# EFR32BG22C224F512IM40 register map
Vendor: Silicon Labs; Series: EFR32; File version: C
Registers are 32-bit, read-write, reset 0x0 unless marked. A register's access mark holds for its fields unless they carry their own. Offsets are from the block's base; [hi:lo] are bit positions; {n}, {i} and the like mark numbered series; 'fields as' and 'values as' point back to an identical list.

## MODEM_S — MODEM_S Registers
Base 0xA8014000
Same registers: MODEM_NS 0xB8014000
0x00 IPVERSION ro reset 0x1
0x04 EN
  [0] EN — Enable peripheral clock to this module
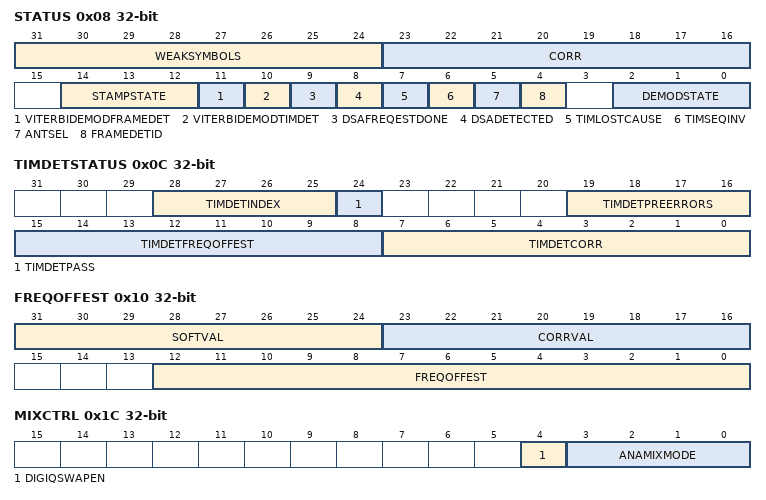
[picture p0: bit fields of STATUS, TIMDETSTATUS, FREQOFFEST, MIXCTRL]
0x08 STATUS ro
  [31:24] WEAKSYMBOLS
  [23:16] CORR — Correlation
  [14:12] STAMPSTATE — BLE Viterbi Demod Timing Stamp
  [11] VITERBIDEMODFRAMEDET — Viterbi Demod frame detected
  [10] VITERBIDEMODTIMDET — Viterbi Demod timing detected
  [9] DSAFREQESTDONE — DSA frequency estimation complete
  [8] DSADETECTED
  [7] TIMLOSTCAUSE — Timing Lost Cause
    0=LOWCORR (Timing lost during Preamble Search or due to low correlation value during Frame Search.); 1=TIMEOUT (Timing lost due to incorrect symbols detected during Frame Search.)
  [6] TIMSEQINV — Timing Sequence Inverted
  [5] ANTSEL — Selected Antenna
    0=ANTENNA0 (Antenna 0 is selected (ANT0 = 1 and ANT1 = 0).); 1=ANTENNA1 (Antenna 1 is selected (ANT0 = 0 and ANT1 = 1).)
  [4] FRAMEDETID — Frame Detected ID
    0=FRAMEDET0 (Last frame was detected with sync word defined in SYNC0.); 1=FRAMEDET1 (Last frame was detected with sync word defined in SYNC1.)
  [2:0] DEMODSTATE
    0=OFF (Off state); 1=TIMINGSEARCH; 2=PRESEARCH (Preamble search); 3=FRAMESEARCH; 4=RXFRAME (Payload Detection); 5=FRAMEDETMODE0 (Timing search with sliding window (FDM0))
0x0C TIMDETSTATUS ro
  [28:25] TIMDETINDEX — Timing detection index
  [24] TIMDETPASS — Timing detection pass
  [19:16] TIMDETPREERRORS — Preamble errors
  [15:8] TIMDETFREQOFFEST — Frequency offset estimate
  [7:0] TIMDETCORR — Correlation value
0x10 FREQOFFEST ro
  [31:24] SOFTVAL — Soft detection value
  [23:16] CORRVAL — Correlation value
  [12:0] FREQOFFEST — Frequency offset estimate
0x14 AFCADJRX ro
  [18:0] AFCADJRX — AFC adjustment for RX
0x18 AFCADJTX ro
  [18:0] AFCADJTX — AFC adjustment for TX
0x1C MIXCTRL
  [4] DIGIQSWAPEN — Digital I/Q swap enable
  [3:0] ANAMIXMODE — Analog receiver mixer mode of operation
    0=NORMAL (The analog mixer operates in its normal mode); 1=IPQPIQSWAP (I path is positive, Q path is positive, I and Q are swapped); 2=IPQN (I path is positive, Q path is negative); 3=IPQNIQSWAP (I path is positive, Q path is negative, I and Q are swapped); 4=INQP (I path is negative, Q path is positive); 5=INQPIQSWAP (I path is negative, Q path is positive, I and Q are swapped); 6=INQN (I path is negative, Q path is negative); 7=INQNIQSWAP (I path is negative, Q path is negative, I and Q are swapped); 8=UPCONVERT (Control the analog receiver mixer such that the analog mixer performs a digital up-conversion on the mixer output, with the frequency set by the DEC0 and CFOSR settings. This mode may be used to perform RF loopback using the normal synthesizer both for transmit and receive, and still get a positive IF frequency on the IF receive signal.); 9=DOWNCONVERT (Control the analog receiver mixer such that the analog mixer performs a digital down-conversion on the mixer output, with the frequency set by the DEC0 and CFOSR settings.)
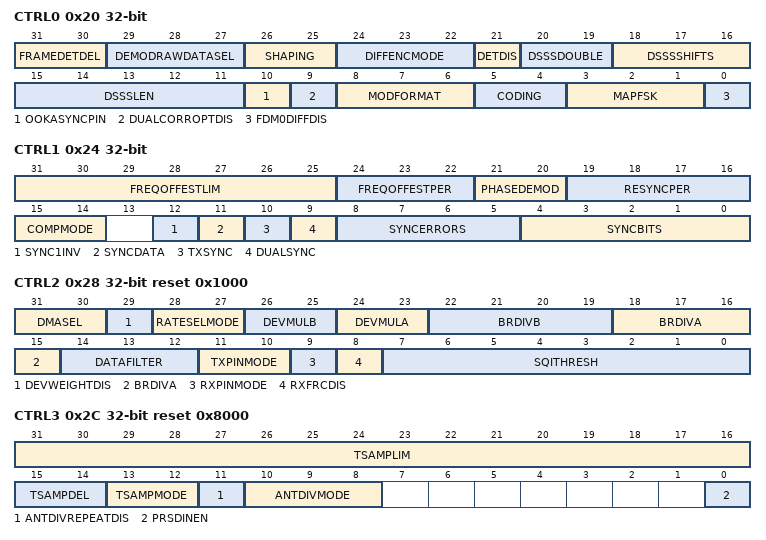
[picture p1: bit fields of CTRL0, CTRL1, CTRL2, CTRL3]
0x20 CTRL0
  [31:30] FRAMEDETDEL — FRAMEDET delay
    0=DEL0 (No delay); 1=DEL8 (8 baud delay); 2=DEL16 (16 baud delay); 3=DEL32 (32 baud delay)
  [29:27] DEMODRAWDATASEL — Demod raw data select
    0=DIS (Disabled.); 1=ENTROPY (1-bit entropy source extracted from the RF receive chain, to be used for random number generation.); 2=ADC (2 * 3-bit I and Q ADC data.); 3=FILTLSB (2 * 16-bit I and Q channel filtered data downmixed to zero-IF. The receive signal chain has 19 bits dynamic range at this point, and the FILTLSB setting outputs the 16 least significant bits (with saturation).); 4=FILTMSB (2 * 16-bit I and Q channel filtered data downmixed to zero-IF. The receive signal chain has 19 bits dynamic range at this point, and the FILTMSB setting outputs the 16 most significant bits (with truncation).); 5=FILTFULL (2 * 19-bit I and Q channel filtered data downmixed to zero-IF. The FILTFULL option will output all 19 bits of dynamic range, sign extended to 32 bits.); 6=FREQ (8-bit received frequency data (or logarithmic amplitude for ASK/OOK).); 7=DEMOD (8-bit demodulated data (freq/amp/phase). When coherent detection is enabled, only the in-phase component is selected.)
  [26:25] SHAPING — Shaping filter
    0=DISABLED (Filter disabled.); 1=ODDLENGTH (Filter has odd length. Filter uses coefficients 0,1,2,3,4,5,6,7,8,7,6,5,4,3,2,1,0.); 2=EVENLENGTH (Filter has even length. Filter uses coefficients 0,1,2,3,4,5,6,7,7,6,5,4,3,2,1,0.); 3=ASYMMETRIC (Filter has asymmetrical coefficients. Filter uses coefficients 0,1,2,3,4,5,6,7.)
  [24:22] DIFFENCMODE — Differential encoding mode
    0=DIS (Differential Encoding is disabled.); 1=RR0 (Transmit the XOR-ed value of the Raw symbol and the last Raw symbol. Initial Raw symbol is 0.); 2=RE0 (Transmit the XOR-ed value of the Raw symbol and the last Encoded symbol. Initial Encoded symbol is 0.); 3=RR1 (Transmit the XOR-ed value of the Raw symbol and the last Raw symbol. Initial Raw symbol is 1.); 4=RE1 (Transmit the XOR-ed value of the Raw symbol and the last Encoded symbol. Initial Encoded symbol is 1.)
  [21] DETDIS — Detection disable
  [20:19] DSSSDOUBLE
    0=DIS (Doubling is disabled.); 1=INV (Doubling is enabled by using inverted symbols.); 2=CONJ (Doubling is enabled by using complex conjugated symbols.)
  [18:16] DSSSSHIFTS
    0=NOSHIFT (No symbols are defined by shifting.); 1=SHIFT1 (Next symbol generated by 1 cyclic shift.); 2=SHIFT2 (Next symbol generated by 2 cyclic shifts.); 3=SHIFT4 (Next symbol generated by 4 cyclic shifts.); 4=SHIFT8 (Next symbol generated by 8 cyclic shifts.); 5=SHIFT16 (Next symbol generated by 16 cyclic shifts.)
  [15:11] DSSSLEN — DSSS length
  [10] OOKASYNCPIN — OOK asynchronous pin mode
  [9] DUALCORROPTDIS — Dual Correlation Optimization Disable
  [8:6] MODFORMAT — Modulation format
    0=FSK2 (Frequency Shift Keying with 2 symbols); 1=FSK4 (Frequency Shift Keying with 4 symbols); 2=BPSK (Binary Phase Shift Keying); 3=DBPSK (Differentially encoded Binary Phase Shift Keying); 4=OQPSK (Half Sine Shaped Offset Quadrature Phase Shift Keying); 5=MSK (Minimum Shift Keying); 6=OOKASK (On Off Keying and Amplitude Shift Keying)
  [5:4] CODING — Symbol coding
    0=NRZ (Non Return to Zero); 1=MANCHESTER (Manchester Coding); 2=DSSS (Direct Sequence Spread Spectrum); 3=LINECODE (Line code. Maps 0 to 0011 symbol and 1 to 1100 symbols)
  [3:1] MAPFSK — Mapping of FSK symbols
    0=MAP0 (4FSK: Symbol 11, 10, 00, 01 for decreasing frequency. 2FSK/MSK/ASK/OOK: Symbol 1 is high/positive frequency or high amplitude, symbol 0 is low/negative frequency or low amplitude.); 1=MAP1 (4FSK: Symbol 01, 00, 10, 11 for decreasing frequency. 2FSK/MSK/ASK/OOK: Symbol 0 is high/negative frequency or high amplitude, symbol 1 is low/negative frequency or low amplitude.); 2=MAP2 (4FSK: Symbol 10, 11, 01, 00 for decreasing frequency. 2FSK/MSK/ASK/OOK: Undefined.); 3=MAP3 (4FSK: Symbol 00, 01, 11, 10 for decreasing frequency. 2FSK/MSK/ASK/OOK: Undefined.); 4=MAP4 (4FSK: Symbol 11, 01, 00, 10 for decreasing frequency. 2FSK/MSK/ASK/OOK: Undefined.); 5=MAP5 (4FSK: Symbol 10, 00, 01, 11 for decreasing frequency. 2FSK/MSK/ASK/OOK: Undefined.); 6=MAP6 (4FSK: Symbol 01, 11, 10, 00 for decreasing frequency. 2FSK/MSK/ASK/OOK: Undefined.); 7=MAP7 (4FSK: Symbol 00, 10, 11, 01 for decreasing frequency. 2FSK/MSK/ASK/OOK: Undefined.)
  [0] FDM0DIFFDIS — Frame Detection Mode 0 disable
0x24 CTRL1
  [31:25] FREQOFFESTLIM — Frequency offset limit
  [24:22] FREQOFFESTPER — Frequency offset estimation period
  [21:20] PHASEDEMOD — Phase demodulation
    0=BDD (Bit Differential Detection.); 1=MBDD (Multibit Differential Detection.)
  [19:16] RESYNCPER — Resync period
  [15:14] COMPMODE — Compensation mode
    0=DIS (Compensation is disabled.); 1=PRELOCK (Compensation locks when preamble is detected.); 2=FRAMELOCK (Compensation locks when frame is detected.); 3=NOLOCK (Compensation is always running)
  [12] SYNC1INV — SYNC1 invert.
  [11] SYNCDATA
    0=DISABLED (SYNC is not part of transmit payload. Modulator adds SYNC in transmit.); 1=ENABLED (SYNC is part of transmit payload. Modulator does not add SYNC in transmit.)
  [10] TXSYNC — Transmit sync word.
    0=SYNC0 (Modulator transmits SYNC0.); 1=SYNC1 (Modulator transmits SYNC1.)
  [9] DUALSYNC — Dual sync words.
    0=DISABLED (Demodulator only searches for SYNC0.); 1=ENABLED (Demodulator searches for SYNC0 and SYNC1 in parallel.)
  [8:5] SYNCERRORS — Maximum number of sync errors
  [4:0] SYNCBITS — Number of sync-word bits
0x28 CTRL2 reset 0x1000
  [31:30] DMASEL — DMA select.
    0=SOFT (SOFTVAL field); 1=CORR (CORRVAL field); 2=FREQOFFEST; 3=POE
  [29] DEVWEIGHTDIS — Deviation weighting disable.
  [28:27] RATESELMODE — Rate select mode
    0=NOCHANGE (No rate change. BRDIVA/DEVMULA is used for entire frame.); 1=PAYLOAD (Change rate for payload. BRDIVA/DEVMULA is used for header and BRDIVB/DEVMULB is used for payload.); 2=FRC (FRC selects between BRDIVA/DEVMULA and BRDIVB/DEVMULB for each symbol in the payload. Header uses BRDIVA/DEVMULA.); 3=SYNC (The configured/detected syncword decides the settings used for the payload. SYNC0 uses BRDIVA/DEVMULA and SYNC1 uses BRDIVB/DEVMULB. Header uses BRDIVA/DEVMULA.)
  [26:25] DEVMULB — Deviation multiplication factor B
  [24:23] DEVMULA — Deviation multiplication factor A
  [22:19] BRDIVB — Baudrate division factor B
  [18:15] BRDIVA — Baudrate division factor A
  [14:12] DATAFILTER
    0=DISABLED (Datafilter disabled); 1=SHORT (Short datafilter enabled. 2*RXBRFRAC should be more than 3.); 2=MEDIUM (Medium datafilter enabled. 2*RXBRFRAC should be more than 4.); 3=LONG (Long datafilter enabled. 2*RXBRFRAC should be more than 5.); {v}=LEN{v+2} (Datafilter with length {v+2} enabled. 2*RXBRFRAC should be more than {v+2}.) (v=4..7)
  [11:10] TXPINMODE — Transmit pin mode
    0=OFF (Pinmode is turned off. Data is gathered from FRC. DOUT/DCLK clocks out transmitted data.); 2=ASYNCHRONOUS (DIN/PRS controls transmitted baud directly. DCLK is set to 0. No support for frame handling nor coding. Only 2-FSK and OOK/ASK can be used.); 3=SYNCHRONOUS (DIN/PRS is sampled on the rising edge of DCLK and used as payload. Frame handling and coding is supported. Only setups with 1 bit per symbol is supported.)
  [9] RXPINMODE — Receive pin mode
    0=SYNCHRONOUS (Detected payload bits are clocked out on DOUT. Only setups with 1 bit per symbol are supported.); 1=ASYNCHRONOUS (DOUT is continuously providing the sign of the detected frequency deviation before offset compensation. Only 2/4-FSK is supported.)
  [8] RXFRCDIS — Receive FRC disable
  [7:0] SQITHRESH — Signal Quality Indicator threshold
0x2C CTRL3 reset 0x8000
  [31:16] TSAMPLIM — Timing Search Amplitude limit
  [15:14] TSAMPDEL — Timing Search Amplitude delay
  [13:12] TSAMPMODE — Timing Search Amplitude Mode
    0=OFF (Amplitude is not used during timing search.); 1=ON (Timing detection is disabled for windows where at least one sample is below limit set by TSAMPLIM.); 2=DIFF (Timing detection is disabled for windows where the difference between samples is higher than the limit set by TSAMPLIM.)
  [11] ANTDIVREPEATDIS — Antenna diversity repeat disable
  [10:8] ANTDIVMODE — Antenna Diversity mode
    0=ANTENNA0 (Antenna 0 (ANT0=1, ANT1=0) is used); 1=ANTENNA1 (Antenna 1 (ANT0=0, ANT1=1) is used); 2=ANTSELFIRST (Select-First algorithm.); 3=ANTSELCORR (Select-Best algorithm based on correlation value.); 4=ANTSELRSSI (Select-Best algorithm based on RSSI value.)
  [0] PRSDINEN — DIN PRS enable
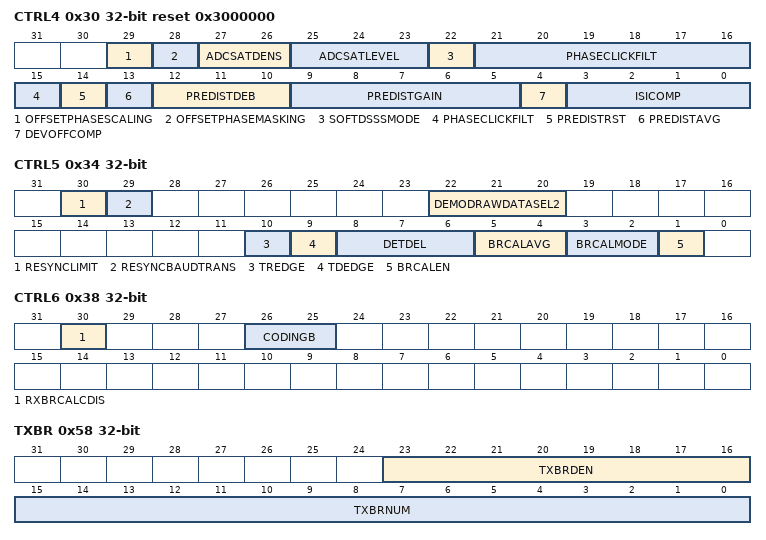
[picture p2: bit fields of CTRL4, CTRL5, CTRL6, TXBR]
0x30 CTRL4 reset 0x3000000
  [29] OFFSETPHASESCALING
  [28] OFFSETPHASEMASKING
  [27:26] ADCSATDENS — ADC Saturation Density setting
  [25:23] ADCSATLEVEL — ADC Saturation Level setting
    0=CONS1 (AGC enters fast loop after first saturation sample.); 1=CONS2 (2 saturation samples required before AGC enters fast loop.); 2=CONS4 (4 saturation samples required before AGC enters fast loop.); 3=CONS8 (8 saturation samples required before AGC enters fast loop.); 4=CONS16 (16 saturation samples required before AGC enters fast loop.); 5=CONS32 (32 saturation samples required before AGC enters fast loop.); 6=CONS64 (64 saturation samples required before AGC enters fast loop.)
  [22] SOFTDSSSMODE
    0=CORR0INV (Soft value is inverted value of symbol-0 correlation value.); 1=CORRDIFF (Soft value is difference between correlation values for symbol-0 and symbol-1.)
  [21:15] PHASECLICKFILT — Phase click filter
  [14] PREDISTRST — Predistortion Reset
  [13] PREDISTAVG — Predistortion Average
    0=AVG8 (Average over 8 samples.); 1=AVG16 (Average over 16 samples.)
  [12:10] PREDISTDEB — Predistortion debounce
  [9:5] PREDISTGAIN — Predistortion gain
  [4] DEVOFFCOMP — Deviation offset compensation
  [3:0] ISICOMP — Inter Symbol Interference compensation
0x34 CTRL5
  [30] RESYNCLIMIT — Resynchronization Limit
    0=HALF (Adjust timing if accumulated timing is higher/lower than RESYNCPER/2.); 1=ALWAYS (Adjust timing if accumulated timing is non-zero.)
  [29] RESYNCBAUDTRANS — Resynchronization Baud Transitions
  [22:20] DEMODRAWDATASEL2 — Demod raw data select 2
    0=DIS (Disabled.); 2=CORR (4-bit max_corr_index and 17-bit max_corr .); 3=CHPW (8-bit channel power and 4-bit BBSSMUX); 4=BBPF (11-bit pre-filter correlation output for BLR and 11-bit pre-filter correlation output for COH demod); 5=FSM (5-bit Narrow-band BLE FSM state, 5-bit Long-range BLE FSM state, 3-bit DSA FSM state, 7-bit Detection FSM State. Captured each time state changes)
  [10] TREDGE — Timing resynchronization edge mode
  [9] TDEDGE — Timing detection edge mode
  [8:6] DETDEL — Detection delay
  [5:4] BRCALAVG — Baudrate calibration averaging
  [3:2] BRCALMODE — Baudrate calibration mode
    0=PEAK (Measure period between peaks in demodulated signal. This mode can give false peaks for high oversampling ratios without sufficient datafiltering.); 1=ZERO (Measure period between zero-crossings in demodulated signal. This mode can miss zero-crossings for high frequency offsets.); 2=PEAKZERO (Combine peak-period and zero-crossing periods. This mode gives best accuracy, but includes weaknesses from both PEAK and ZERO modes.)
  [1] BRCALEN — Baudrate calibration enable
0x38 CTRL6
  [30] RXBRCALCDIS — RX Baudrate Calculation Disable
  [26:25] CODINGB — Coding format
    values as CTRL0.CODING
0x58 TXBR
  [23:16] TXBRDEN — Transmit baudrate denominator
  [15:0] TXBRNUM — Transmit baudrate numerator
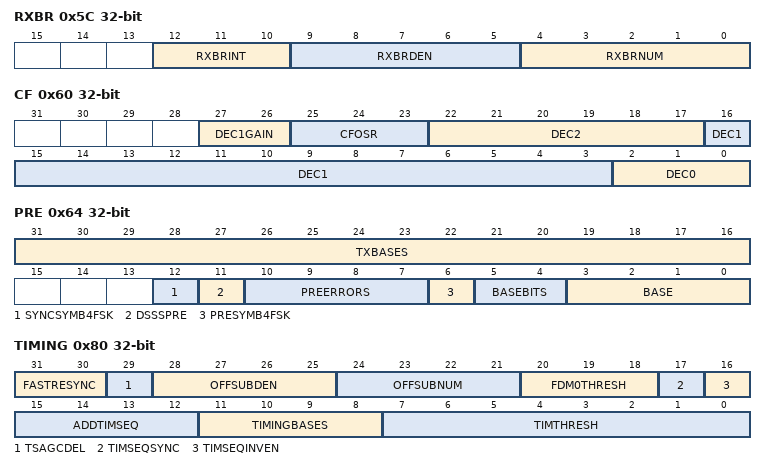
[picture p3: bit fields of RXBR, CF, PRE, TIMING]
0x5C RXBR
  [12:10] RXBRINT — Receive baudrate integer
  [9:5] RXBRDEN — Receive baudrate denominator
  [4:0] RXBRNUM — Receive baudrate numerator
0x60 CF
  [27:26] DEC1GAIN — Second decimation filter gain
    0=ADD0 (No additional gain. Suggested setting for BW higher than 1kHz); 1=ADD6 (6 dB additional gain. Suggested setting for BW between 250 Hz and 1 kHz); 2=ADD12 (12 dB additional gain. Suggested setting for BW less than 250 Hz)
  [25:23] CFOSR — Center Frequency Oversampling Ratio
    0=CF7 (Oversampling ratio = 7); 1=CF8 (Oversampling ratio = 8); 2=CF12 (Oversampling ratio = 12); 3=CF16 (Oversampling ratio = 16); 4=CF32 (Oversampling ratio = 32); 5=CF0 (Center frequency set to 0)
  [22:17] DEC2 — Third decimation
  [16:3] DEC1 — Second decimation
  [2:0] DEC0 — First decimation
    0=DF3 (Decimation Factor 0 = 3. Cutoff 0.050 * f<subscript>HFXO</subscript>.); 1=DF4WIDE (Decimation Factor 0 = 4. Cutoff 0.069 * f<subscript>HFXO</subscript>.); 2=DF4NARROW (Decimation Factor 0 = 4. Cutoff 0.037 * f<subscript>HFXO</subscript>.); 3=DF8WIDE (Decimation Factor 0 = 8. Cutoff 0.012 * f<subscript>HFXO</subscript>.); 4=DF8NARROW (Decimation Factor 0 = 8. Cutoff 0.005 * f<subscript>HFXO</subscript>.)
0x64 PRE
  [31:16] TXBASES
  [12] SYNCSYMB4FSK — Sync symbols 4FSK
    0=FSK2 (The syncword is 2FSK modulated. Each bit in SYNCn is encoded as a positive or negative deviation. The deviation is controlled by PRESYMB4FSK.); 1=FSK4 (The syncword is 4FSK modulated. Every two bits in SYNCn are encoded as a 4FSK symbol.)
  [11] DSSSPRE — DSSS preamble
  [10:7] PREERRORS — Preamble errors
  [6] PRESYMB4FSK — Preamble symbols 4-FSK
    0=OUTER (Symbols corresponding to +/- 3dev.); 1=INNER (Symbols corresponding to +/- dev.)
  [5:4] BASEBITS
  [3:0] BASE — Preamble base
0x68 SYNC0
  [31:0] SYNC0 — Sync-word 0
0x6C SYNC1
  [31:0] SYNC1 — Sync word 1
0x80 TIMING
  [31:30] FASTRESYNC — Fast timing resynchronization
    0=DIS (Disabled.); 1=PREDET (Allow fast resynchronization until preamble is detected.); 2=FRAMEDET (Allow fast resynchronization until frame is detected.)
  [29] TSAGCDEL — Timing Search AGC delay
  [28:25] OFFSUBDEN — Offset subperiod denominator
  [24:21] OFFSUBNUM — Offset subperiod numerator
  [20:18] FDM0THRESH — Frame Detection Mode 0 threshold
  [17] TIMSEQSYNC — Timing sequence part of sync-word
  [16] TIMSEQINVEN — Timing sequence inversion enable
  [15:12] ADDTIMSEQ — Additional timing sequences
  [11:8] TIMINGBASES
  [7:0] TIMTHRESH — Timing threshold
0x84 DSSS0
  [31:0] DSSS0 — DSSS symbol 0
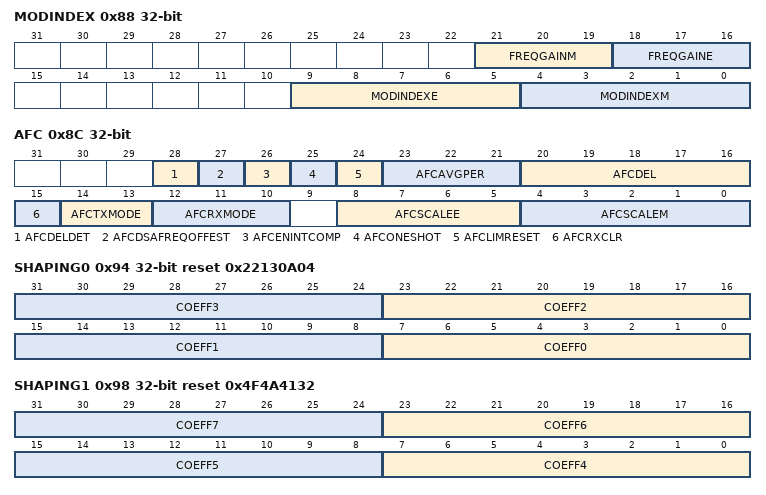
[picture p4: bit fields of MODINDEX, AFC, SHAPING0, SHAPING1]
0x88 MODINDEX
  [21:19] FREQGAINM — Frequency demodulation gain - mantissa
  [18:16] FREQGAINE — Frequency demodulation gain - exponent
  [9:5] MODINDEXE — Modulation index exponent.
  [4:0] MODINDEXM — Modulation index mantissa.
0x8C AFC
  [28] AFCDELDET — Delay Detection state machine
  [27] AFCDSAFREQOFFEST — Consider frequency offset estimation
  [26] AFCENINTCOMP — Internal frequency offset compensation
  [25] AFCONESHOT — AFC One-Shot feature
  [24] AFCLIMRESET — Reset AFCADJRX value
  [23:21] AFCAVGPER — AFC average period
  [20:16] AFCDEL — AFC delay
  [15] AFCRXCLR — AFCRX clear mode
  [14:13] AFCTXMODE
    0=DIS (Disabled.); 1=PRELOCK (AFCADJTX loaded from AFCADJRX when preamble is detected.); 2=FRAMELOCK (AFCADJTX loaded from AFCADJRX when frame is detected.)
  [12:10] AFCRXMODE
    0=DIS (Disabled.); 1=FREE (Free running. AFCADJRX constantly updated.); 2=FREEPRESTART (Free running. AFCADJRX not updated before preamble is detected.); 3=TIMLOCK (AFCADJRX locked when timing is detected.); 4=PRELOCK (AFCADJRX locked when preamble is detected.); 5=FRAMELOCK (AFCADJRX locked when frame is detected.); 6=FRAMELOCKPRESTART (AFCADJRX not updated before preamble is detected and locked when frame is detected.)
  [8:5] AFCSCALEE — AFC scaling exponent
  [4:0] AFCSCALEM — AFC scaling mantissa
0x90 AFCADJLIM
  [17:0] AFCADJLIM — AFC adjustment limit
0x94 SHAPING0 reset 0x22130A04
  [8n+7:8n] COEFF{n} (n=0..3) — Shaping Coefficient {n}
0x98 SHAPING1 reset 0x4F4A4132
  [8n-25:8n-32] COEFF{n} (n=4..7) — Shaping Coefficient {n}
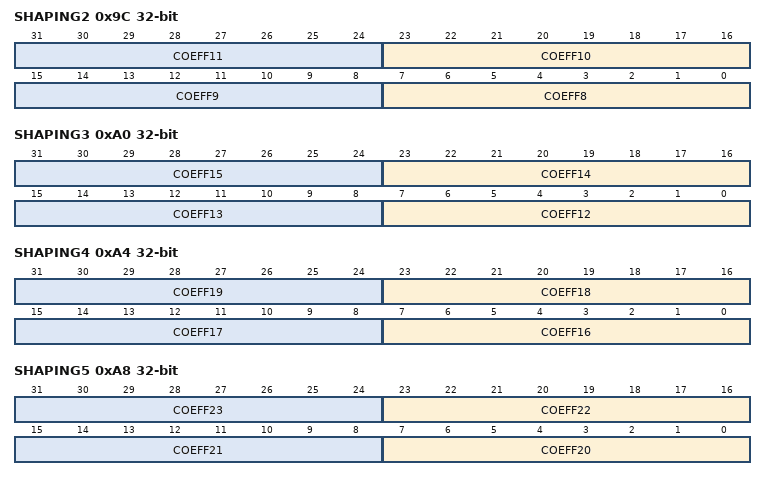
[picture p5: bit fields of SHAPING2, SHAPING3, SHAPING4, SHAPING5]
0x9C SHAPING2
  [8n-57:8n-64] COEFF{n} (n=8..11) — Shaping Coefficient {n}
0xA0 SHAPING3
  [8n-89:8n-96] COEFF{n} (n=12..15) — Shaping Coefficient {n}
0xA4 SHAPING4
  [8n-121:8n-128] COEFF{n} (n=16..19) — Shaping Coefficient {n}
0xA8 SHAPING5
  [8n-153:8n-160] COEFF{n} (n=20..23) — Shaping Coefficient {n}
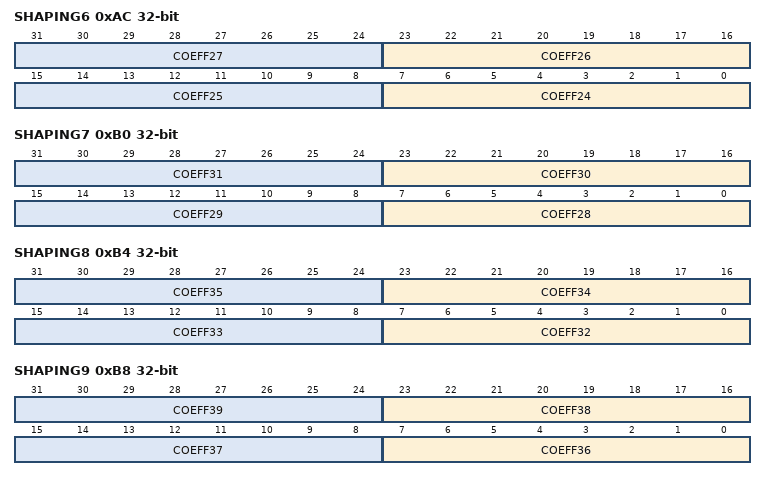
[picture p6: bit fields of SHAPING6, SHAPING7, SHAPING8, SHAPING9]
0xAC SHAPING6
  [8n-185:8n-192] COEFF{n} (n=24..27) — Shaping Coefficient {n}
0xB0 SHAPING7
  [8n-217:8n-224] COEFF{n} (n=28..31) — Shaping Coefficient {n}
0xB4 SHAPING8
  [8n-249:8n-256] COEFF{n} (n=32..35) — Shaping Coefficient {n}
0xB8 SHAPING9
  [8n-281:8n-288] COEFF{n} (n=36..39) — Shaping Coefficient {n}
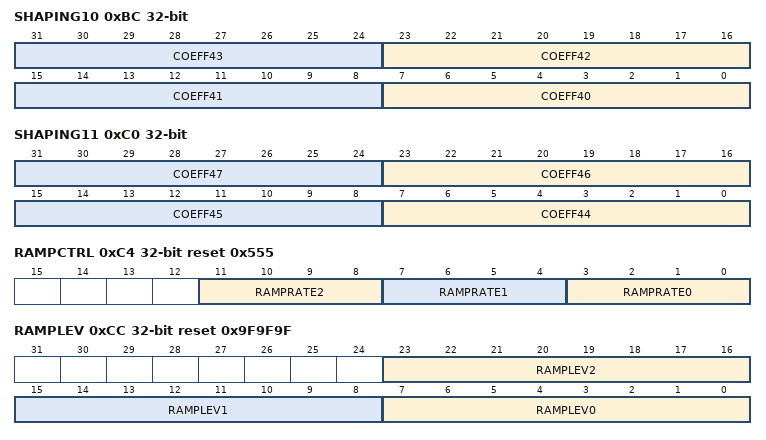
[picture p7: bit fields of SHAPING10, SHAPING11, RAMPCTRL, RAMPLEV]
0xBC SHAPING10
  [8n-313:8n-320] COEFF{n} (n=40..43) — Shaping Coefficient {n}
0xC0 SHAPING11
  [8n-345:8n-352] COEFF{n} (n=44..47) — Shaping Coefficient {n}
0xC4 RAMPCTRL reset 0x555
  [11:8] RAMPRATE2, [7:4] RAMPRATE1, [3:0] RAMPRATE0
0xCC RAMPLEV reset 0x9F9F9F
  [23:16] RAMPLEV2 — Ramp level 2
  [15:8] RAMPLEV1 — Ramp level 1
  [7:0] RAMPLEV0 — Ramp level 0
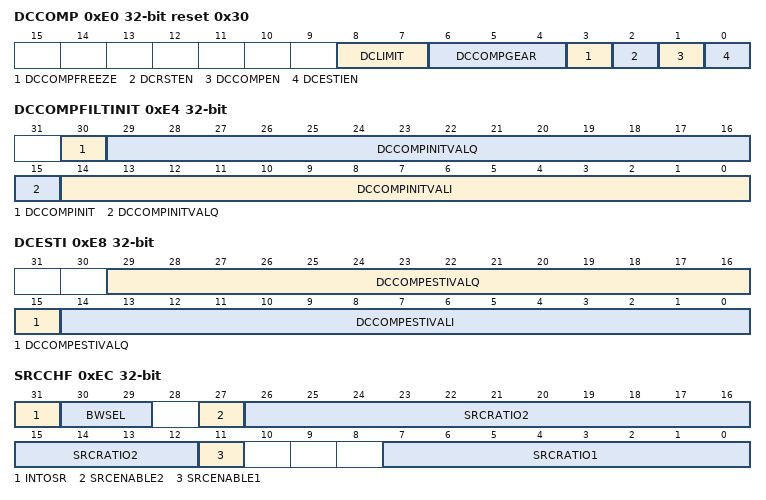
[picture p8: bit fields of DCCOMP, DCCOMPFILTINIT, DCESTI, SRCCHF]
0xE0 DCCOMP reset 0x30
  [8:7] DCLIMIT — DC offset limit
    0=FULLSCALE (1000 mV); 1=FULLSCALEBY4 (250 mV); 2=FULLSCALEBY8 (125 mV); 3=FULLSCALEBY16 (62 mV)
  [6:4] DCCOMPGEAR — DC Offset Compensation Filter Gear
  [3] DCCOMPFREEZE — DC Offset Compensation Filter Freeze
  [2] DCRSTEN — DC Compensation Filter Reset Enable
  [1] DCCOMPEN — DC Offset Compensation Enable
  [0] DCESTIEN — DC Offset Estimation Enable
0xE4 DCCOMPFILTINIT
  [30] DCCOMPINIT — Initialize filter state
  [29:15] DCCOMPINITVALQ — Q-channel initialization value
  [14:0] DCCOMPINITVALI — I-channel initialization value
0xE8 DCESTI ro
  [29:15] DCCOMPESTIVALQ — Q-channel DC-Offset Estimated value
  [14:0] DCCOMPESTIVALI — I-channel DC-Offset Estimated value
0xEC SRCCHF
  [31] INTOSR — Forcing Integer OSR
  [30:29] BWSEL — Channel filter bandwidth
    0=wide bandwidth selected ; BW = 0.263*Fxtal/dec0-factor/dec1-factor; 1=wide bandwidth selected ; BW = 0.263*Fxtal/dec0-factor/dec1-factor; 2=X2 (narrow bandwidth selected ; BW = 0.196*Fxtal/dec0-factor/dec1-factor); 3=X3 (narrow bandwidth selected ; BW = 0.196*Fxtal/dec0-factor/dec1-factor)
  [27] SRCENABLE2 — SRC2 enable
  [26:12] SRCRATIO2 — Q-channel SRC ratio
  [11] SRCENABLE1 — SRC1 enable
  [7:0] SRCRATIO1 — I-channel SRC ratio
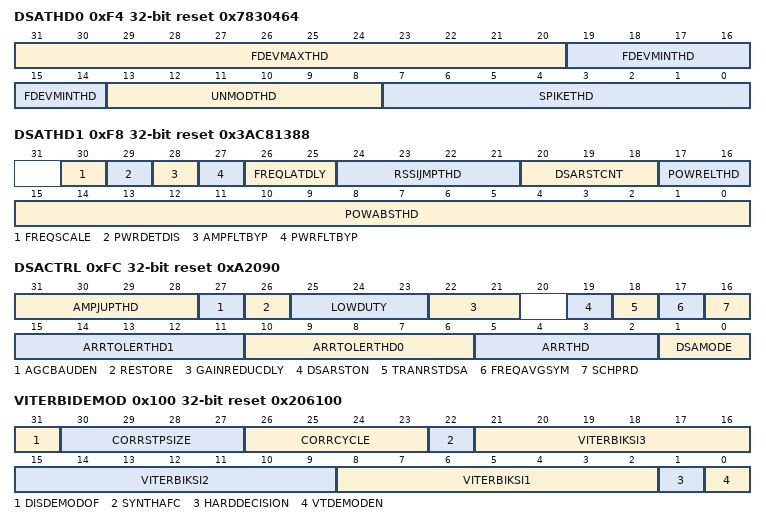
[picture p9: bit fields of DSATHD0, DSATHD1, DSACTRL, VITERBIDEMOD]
0xF4 DSATHD0 reset 0x7830464
  [31:20] FDEVMAXTHD — Frequency deviation maximum threshold
  [19:14] FDEVMINTHD — Frequency deviation minimum threshold
  [13:8] UNMODTHD — Unmodulated carrier detector threshold
  [7:0] SPIKETHD — Spike threshold
0xF8 DSATHD1 reset 0x3AC81388
  [30] FREQSCALE — Frequency scale factor
  [29] PWRDETDIS — Power detection disabled
  [28] AMPFLTBYP — Amplitude filter bypass
  [27] PWRFLTBYP — Power filter bypass
  [26:25] FREQLATDLY — Frequency late delay
  [24:21] RSSIJMPTHD — RSSI jump detector threshold
  [20:18] DSARSTCNT — DSA reset counter
  [17:16] POWRELTHD — Relative power detector threshold
    0=DISABLED (Threshold is 6dB. The relative power detector will trigger when the current RSSI is 6dB stronger than the previously detected RSSI.); 1=MODE1 (Threshold is 9dB. The relative power detector will trigger when the current RSSI is 9dB stronger than the previously detected RSSI.); 2=MODE2 (Threshold is 12dB. The relative power detector will trigger when the current RSSI is 12dB stronger than the previously detected RSSI.); 3=MODE3 (Threshold is 15dB. The relative power detector will trigger when the current RSSI is 15dB stronger than the previously detected RSSI.)
  [15:0] POWABSTHD — Power absolute threshold
0xFC DSACTRL reset 0xA2090
  [31:28] AMPJUPTHD — Amplitude jump detection thrshold
  [27] AGCBAUDEN — Consider Baud_en from AGC
  [26] RESTORE — Power detector reset of DSA
  [25:23] LOWDUTY — Low duty cycle delay
  [22:21] GAINREDUCDLY — Detection Delay of AGC gain reduction
  [19] DSARSTON — DSA detection reset
  [18] TRANRSTDSA — power transient detector Reset DSA
  [17] FREQAVGSYM — DSA frequency estimation averaging
    0=AVG2TS (Frequency estimation over 2 symbol periods.); 1=AVG4TS (Frequency estimation over 4 symbol periods.)
  [16] SCHPRD — Search period window length
    0=TS2 (The search period is 2 symbol periods.); 1=TS4 (The search period is 4 symbol periods.)
  [15:11] ARRTOLERTHD1 — Arrival tolerance threshold 1
  [10:6] ARRTOLERTHD0 — Arrival tolerance threshold 0
  [5:2] ARRTHD — Signal arrival valid counter threshold
  [1:0] DSAMODE — Mode of Digital Signal Arrival detector
    0=DISABLED (DSA is disabled); 1=ENABLED (DSA is enabled by the relative/absolute RSSI detector and is reset by using detectors for spike content and frequency deviation. The RSSI jump detector is used to recover from false detects.)
0x100 VITERBIDEMOD reset 0x206100
  [31] DISDEMODOF — Disable Demod Over Flow Detection
  [30:27] CORRSTPSIZE — Correction step size
  [26:23] CORRCYCLE — Correction cycles
  [22] SYNTHAFC — Synthesizer AFC in Viterbi demod
  [21:16] VITERBIKSI3
  [15:9] VITERBIKSI2
  [8:2] VITERBIKSI1
  [1] HARDDECISION
  [0] VTDEMODEN — Viterbi demodulator enable
0x104 VTCORRCFG0 reset 0x123556B7
  [31:0] EXPECTPATT — Expected pattern
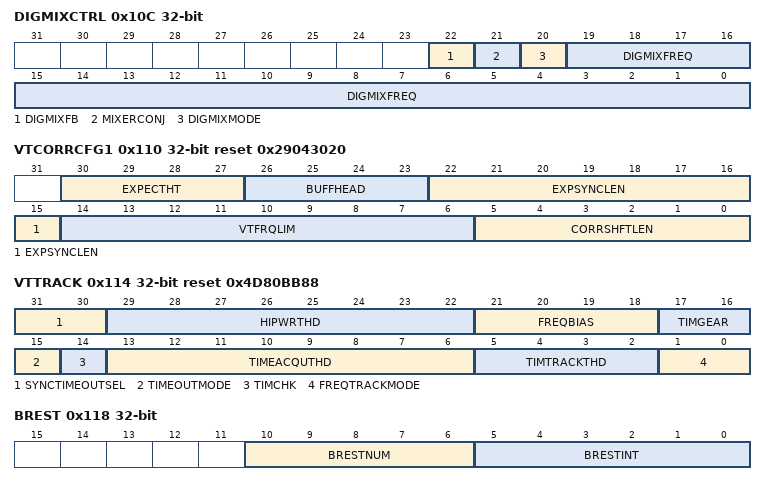
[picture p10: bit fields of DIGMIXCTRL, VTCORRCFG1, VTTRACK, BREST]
0x10C DIGMIXCTRL
  [22] DIGMIXFB — Digital mixer Frequency Correction
  [21] MIXERCONJ — Digital mixer input conjugate
  [20] DIGMIXMODE — Digital mixer frequency control
    0=CFOSR (Mixer frequency specified by CFOSR.); 1=DIGMIXFREQ (Mixer frequency specified by DIGMIXFREQ.)
  [19:0] DIGMIXFREQ — Digital mixer frequency control word
0x110 VTCORRCFG1 reset 0x29043020
  [30:27] EXPECTHT — Expected patterns head and tail
  [26:23] BUFFHEAD — Buffer header
  [22:15] EXPSYNCLEN — Expected sync length
  [14:6] VTFRQLIM — Viterbi frequency limiter
  [5:0] CORRSHFTLEN — Correlator shift length
0x114 VTTRACK reset 0x4D80BB88
  [31:30] SYNCTIMEOUTSEL — SYNC-WORD DET TIMEOUT
  [29:22] HIPWRTHD — High Power detection threshold
  [21:18] FREQBIAS — Frequency estimation bias
  [17:16] TIMGEAR — Timing Gear
    0=GEAR0 (Execute timing tracking regardless of difference between Early/Late and Current correlation values. Referred to as fast gear. Same as GEAR3); 1=GEAR1 (Execute timing tracking only when correlation value of Early/Late is 75% or less of the Current correlation value. Referred to as medium gear.); 2=GEAR2 (Execute timing tracking only when correlation value of Early/Late is 50% or less of the Current correlation value. Referred to as slow gear.)
  [15] TIMEOUTMODE
  [14] TIMCHK — Time check
  [13:6] TIMEACQUTHD — Time acquisition threshold
  [5:2] TIMTRACKTHD — Timing tracking threshold
  [1:0] FREQTRACKMODE — Frequency tracking mode
    0=DISABLED (Frequency tracking disabled. Only a one-time frequency offset compensation applied through DSA.); 1=MODE1 (Frequency tracking enabled with one correction, when needed, every 16 symbol periods.); 2=MODE2 (Frequency tracking enabled with one correction, when needed, every 32 symbol periods.); 3=MODE3 (Frequency tracking enabled with one correction, when needed, every 48 symbol periods.)
0x118 BREST ro
  [10:6] BRESTNUM — Fractional part of estimated baudrate
  [5:0] BRESTINT — Integer part of estimated baudrate
0x124 AUTOCG
  [15:0] AUTOCGEN — Enable automatic clock gating
0x128 CGCLKSTOP
  [15:0] FORCEOFF — Manual control clocks
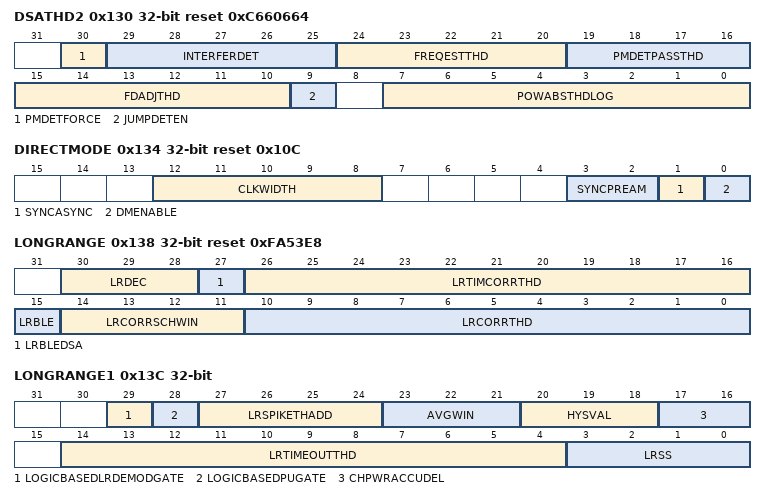
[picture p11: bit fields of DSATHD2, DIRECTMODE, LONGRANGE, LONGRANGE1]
0x130 DSATHD2 reset 0xC660664
  [30] PMDETFORCE — Force DSA preamble detector
  [29:25] INTERFERDET — Interference detection threshold
  [24:20] FREQESTTHD — Frequency Estimation Timeout Threshold
  [19:16] PMDETPASSTHD — DSA Preamble detection counter threshold
  [15:10] FDADJTHD — Frequency deviation ripple threshold
  [9] JUMPDETEN — Power jump detection enable
  [7:0] POWABSTHDLOG — Power threshold in logarithm-scale
0x134 DIRECTMODE reset 0x10C
  [12:8] CLKWIDTH — Synchronous mode clock pulse width
  [3:2] SYNCPREAM — Synchronous mode preamble
    0=ADD0 (No preamble bits appended); 1=ADD8 (8 preamble bits appended); 2=ADD16 (16 preamble bits appended); 3=ADD32 (32 preamble bits appended)
  [1] SYNCASYNC — Choose Synchronous or Asynchronous mode
  [0] DMENABLE — Enable Direct Mode
0x138 LONGRANGE reset 0xFA53E8
  [30:28] LRDEC — DEC value
  [27] LRBLEDSA — DSA enable
  [26:16] LRTIMCORRTHD — Correlator threshold
  [15] LRBLE — Enable
  [14:11] LRCORRSCHWIN — Window size
  [10:0] LRCORRTHD — Correlator threshold
0x13C LONGRANGE1
  [29] LOGICBASEDLRDEMODGATE — Logic Based Long Range Demod Gating
  [28] LOGICBASEDPUGATE — Logic Based Phase Unwrap Gating
  [27:24] LRSPIKETHADD — Long Range DSA spike threshold addition
  [23:21] AVGWIN — Average window
  [20:18] HYSVAL — Hysteresis Value for BBSS
  [17:16] CHPWRACCUDEL — Channel Power Accumulated Delay
    0=DEL0 (Use accumulated channel power value); 1=DEL32 (Delayed by 32 chips); 2=DEL64 (Delayed by 64 chips)
  [14:4] LRTIMEOUTTHD — Long Range Time Out Threshold
  [3:0] LRSS — Long Range Signal Selection
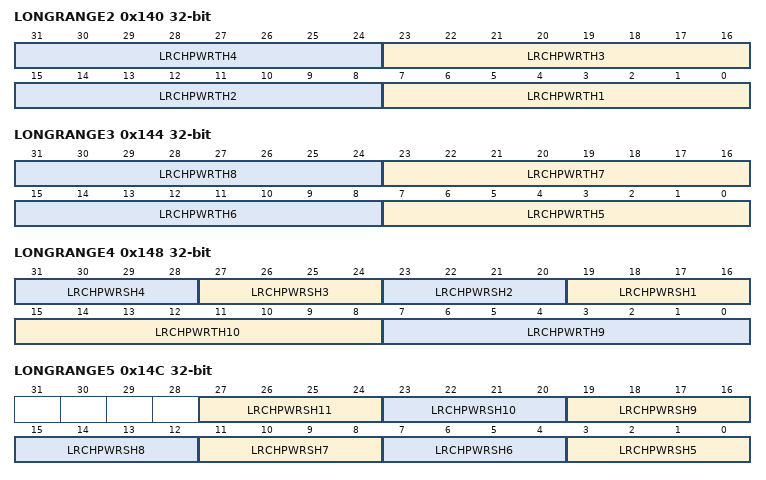
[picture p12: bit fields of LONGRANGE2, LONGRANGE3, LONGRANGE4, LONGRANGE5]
0x140 LONGRANGE2
  [8n-1:8n-8] LRCHPWRTH{n} (n=1..4) — Long Range channel power threshold
0x144 LONGRANGE3
  [8n-33:8n-40] LRCHPWRTH{n} (n=5..8) — Long Range channel power threshold
0x148 LONGRANGE4
  [4n+15:4n+12] LRCHPWRSH{n} (n=1..4) — Long Range channel power shift
  [15:8] LRCHPWRTH10 — Long Range channel power threshold
  [7:0] LRCHPWRTH9 — Long Range channel power threshold
0x14C LONGRANGE5
  [4n-17:4n-20] LRCHPWRSH{n} (n=5..11) — Long Range channel power shift
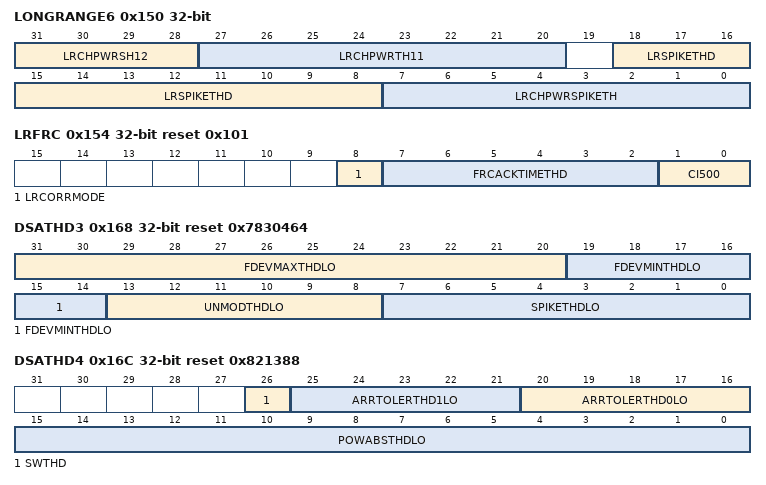
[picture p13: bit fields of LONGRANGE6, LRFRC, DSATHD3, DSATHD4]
0x150 LONGRANGE6
  [31:28] LRCHPWRSH12 — Long Range channel power shift
  [27:20] LRCHPWRTH11 — Long Range channel power threshold
  [18:8] LRSPIKETHD — Long Range spike threshold
  [7:0] LRCHPWRSPIKETH — Long Range channel power spike threshold
0x154 LRFRC reset 0x101
  [8] LRCORRMODE — LR Correlator operation Mode
  [7:2] FRCACKTIMETHD — FRC acknowledge timeout threshold
  [1:0] CI500 — Long Range CI mapping for 500kbps
0x168 DSATHD3 reset 0x7830464
  [31:20] FDEVMAXTHDLO — Frequency deviation maximum threshold
  [19:14] FDEVMINTHDLO — Frequency deviation minimum threshold
  [13:8] UNMODTHDLO — Unmodulated carrier detector threshold
  [7:0] SPIKETHDLO — Spike threshold
0x16C DSATHD4 reset 0x821388
  [26] SWTHD — Enable switch threshold for low power
  [25:21] ARRTOLERTHD1LO — Arrival tolerance threshold 1
  [20:16] ARRTOLERTHD0LO — Arrival tolerance threshold 0
  [15:0] POWABSTHDLO — Power absolute threshold for low power
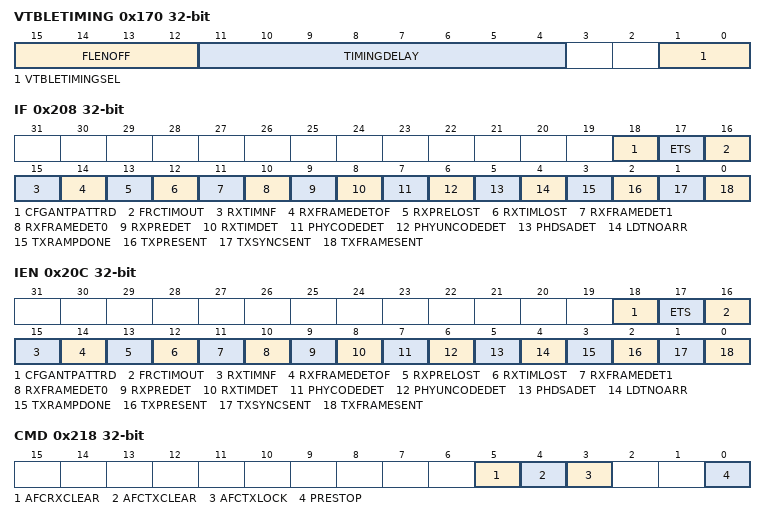
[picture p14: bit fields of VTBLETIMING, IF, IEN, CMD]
0x170 VTBLETIMING
  [15:12] FLENOFF — Timing Stamp Frame Length Offset
  [11:4] TIMINGDELAY — Viterbi BLE Delay timer
  [1:0] VTBLETIMINGSEL — Viterbi BLE timing stamp selection
    0=FRAMEDET_DELAY (Delayed frame detection will be used as Timing stamp. This mode should be selected for legacy demod and Long Range BLE demod.); 1=END_FRAME_PULSE (The end of frame detection from Narrow Viterbi demod will be used as Timing stamp. This signal is a narrow pulse signal and pulse width is one xo clock cycle.); 2=END_FRAME (The end of frame detection from Narrow Viterbi demod will be used as Timing stamp. This signal is a wdie pulse signal); 3=INV_END_FRAME (For testing only.)
0x208 IF
  [18] CFGANTPATTRD — cfg
  [17] ETS — Early Time Stamp detect
  [16] FRCTIMOUT — DEMOD-FRC req/ack timeout
  [15] RXTIMNF — Timing not found
  [14] RXFRAMEDETOF — Frame detection overflow
  [13] RXPRELOST — Preamble lost
  [12] RXTIMLOST — Timing lost
  [11] RXFRAMEDET1 — Frame with sync-word 1 detected
  [10] RXFRAMEDET0 — Frame with sync-word 0 detected
  [9] RXPREDET — Preamble detected
  [8] RXTIMDET — Timing detected
  [7] PHYCODEDET — CONCURRENT CODED PHY DET
  [6] PHYUNCODEDET — CONCURRENT UNCODED PHY DET
  [5] PHDSADET — PHASE DSA DETECT
  [4] LDTNOARR — No signal Detected in LDT
  [3] TXRAMPDONE — Mod ramper idle
  [2] TXPRESENT — Preamble sent
  [1] TXSYNCSENT — Sync word sent
  [0] TXFRAMESENT — Frame sent
0x20C IEN
  [18] CFGANTPATTRD
  [17] ETS — Early Time Stamp detect
  [16] FRCTIMOUT — DEMOD-FRC req/ack timeout
  [15] RXTIMNF — Timing not found
  [14] RXFRAMEDETOF — Frame detection overflow
  [13] RXPRELOST — Preamble lost
  [12] RXTIMLOST — Timing lost
  [11] RXFRAMEDET1 — Frame with sync-word 1 detected
  [10] RXFRAMEDET0 — Frame with sync-word 0 detected
  [9] RXPREDET — Preamble detected
  [8] RXTIMDET — Timing detected
  [7] PHYCODEDET — CONCURRENT CODED PHY DET
  [6] PHYUNCODEDET — CONCURRENT UNCODED PHY DET
  [5] PHDSADET — PHASE DSA DETECT
  [4] LDTNOARR — No signal Detected in LDT
  [3] TXRAMPDONE — Mod ramper idle
  [2] TXPRESENT — Preamble sent
  [1] TXSYNCSENT — Sync word sent
  [0] TXFRAMESENT — Frame sent
0x218 CMD wo
  [5] AFCRXCLEAR — Clear AFC RX compensation.
  [4] AFCTXCLEAR — Clear AFC TX compensation.
  [3] AFCTXLOCK — Lock AFC TX compensation
  [0] PRESTOP — Preamble stop
0x21C FSMSTATUS ro
  [23:20] ANTDIVSTATE — Antenna diversity control state
    0=IDLE (Idle state); 1=FIRST_ANT0 (First ANT0 selection); 2=FIRST_ANT1 (First ANT1 selection); 3=TIMSEARCH_ANT0 (Timing search on ANT0); 4=TIMSEARCH_ANT1 (Timing search on ANT1); 5=TIMDET_ANT0 (Check ANT1 after timing detecton ANT0); 6=TIMDET_ANT1 (Check ANT0 after timing detecton ANT1); 7=EVALUATE (Evaluate and select better antenna); 8=TIMSEARCH_SELECTED (Searching on better antenna); 9=TIMDET_SELECTED (Selected better antenna); 10=REPEAT_ANT0; 11=REPEAT_ANT1; 15=MANUAL (Manual mode)
  [19:15] NBBLESTATE — Demodulator Narrow-band BLE FSM state
    0=IDLE (IDLE state); 1=VTINITI; 2=ADDRNXT; 3=INICOST; 4=CALCCOST; 5=INITALACQU; 6=INITALCOSTCALC; 7=MINCOSTCALC; 8=FREQACQU; 9=FREQACQUDONE; 10=TIMINGACQUEARLY; 11=TIMINGACQUCURR; 12=TIMINGACQULATE; 13=TIMINGACQUDONE; 14=VIRTBIINIT0; 15=VIRTBIINIT1; 16=VIRTBIRXSYNC; 17=VIRTBIRXPAYLOAD; 18=HARDRXSYNC; 19=HARDXPAYLOAD (HARD_RXPAYLOAD); 20=TRACKFREQ; 21=TRACKTIMEARLY; 22=TRACKTIMCURR; 23=TRACKTIMLATE; 24=TRACKDONE; 25=TRACKDECISION; 26=STOP; 27=WAITACK; 28=DEBUG
  [14:10] LRBLESTATE — Demodulator long-range BLE FSM state
    0=IDLE (IDLE state); 1=CLEANUP; 2=CORRCOE; 3=WAITLRDSA; 4=MAXCORR; 5=WAITRDY; 6=FEC1DATA; 7=FEC1ACK; 8=PAUSE; 9=FEC2DATA; 10=FEC2ACK; 11=TRACKCUR; 12=TRACKEAR; 13=TRACKLAT; 14=TRACKDONE; 15=TDECISION; 16=STOP
  [9:7] DSASTATE — Demodulator DSA FSM state
    0=IDLE (IDLE state); 1=ARRIVALCHK (Arrival Check); 2=STATUSCHK (Status Check); 3=SAMPPW; 4=WAITPWRUP; 5=WAITDSALO; 6=WAITABORT; 7=STOP
  [6:0] DETSTATE — Detection FSM state
    0=OFF (Off state); 10=TIMINGSEARCH; 20=PRESEARCH (Preamble search); 30=FRAMESEARCH; 40=RXFRAME (Payload Detection); 50=FRAMEDETMODE0 (Timing search with sliding window (FDM0))
0x220 STATUS2 ro
  [31:18] RTVTCORR — VT demod Correlation
  [15] CODEDPHY — CODED PHY DET
  [14] UNCODEDPHY — UNCODED PHY DET
  [13:12] LRBLECI — RXed packet's LR BLE coding indicator
    0=LR125k (FEC block 2 coded using C=8, 125kbps); 1=LR500k (FEC block 2 coded using C=2, 500kbps)
  [11:8] BBSSMUX — Actual Baseband Signal Selection
  [7:0] CHPWRACCUMUX — Channel power
0x224 STATUS3 ro
  [26] SYNCSECPEAKABTH — SYNC second peak above threshold
  [24] LRDSADET — DSA prefilter above LRSPIKETHD
  [22] LRDSALIVE — BLRDSA Prefilter above LRSPIKETHD
  [21:11] BBPFOUTABS — Pre-filter Correlation Output for BLR
  [10:0] BBPFOUTABS1 — Pre-filter Correlation Output
0x228 IRCAL
  [15] IRCALIFADCDBG
  [14] IRCALCOEFRSTCMD wo — IRCAL coef reset cmd
  [13] IRCORREN — IR Correction enable bit
  [12:7] MUISHF — MUI shift value
  [5:1] MURSHF — MUR shift value
  [0] IRCALEN — IRCAL enable bit
0x22C IRCALCOEF ro
  [30:16] CIV — CIV coefficient
  [14:0] CRV — CRV coefficient
0x230 BLEIQDSA
  [31:18] BLEIQDSADIFFTH1 — BLEIQDSA BLEIQDSADIFFTH1
  [17:15] BLEIQDSAIIRCOEFPWR
  [14:1] BLEIQDSATH — BLEIQDSA Threshold
  [0] BLEIQDSAEN — BLEIQDSA Enable
0x234 BLEIQDSAEXT1 reset 0xE000000
  [29] IIRRST — IIR Reset
  [28:25] MAXCORRCNTIQDSA
  [24:11] BLEIQDSATHCOMB — Threshold when i and q are added
  [10:7] BLEIQDSAADDRBIAS
  [6:5] CORRIIRAVGMULFACT — Corr IIR Avg Multiplication Factor
  [4:3] CHPWRFIRAVGVAL — Channel Power FIR Avg Value
    0=AVG0 (No Avg); 1=AVG2 (2 sample avg); 2=AVG4 (4 sample avg); 3=AVG8 (8 sample avg)
  [2] CHPWRFIRAVGEN — Channel Power FIR Avg Enable
  [1:0] FREQSCALEIQDSA — I/Q DSA Frequency scale
0x238 SYNCPROPERTIES
  [7:1] SYNCSECPEAKTH — SYNC auto corr second peak threshold
  [0] SYNCCORRCLR — Sync auto corr clear bit
0x23C DIGIGAINCTRL
  [8] DEC0GAIN — DEC0 Gain Select
  [7] DIGIGAINHALF — Digital Gain Halved
  [6] DIGIGAINDOUBLE — Digital Gain Doubled
  [5:1] DIGIGAINSEL — Digital Gain Select
    0=GAINM3; 1=GAINM2P75; 2=GAINM2P5; 3=GAINM2P25; 4=GAINM2; 5=GAINM1P75; 6=GAINM1P5; 7=GAINM1P25; 8=GAINM1; 9=GAINM0P75; 10=GAINM0P5; 11=GAINM0P25; 12=GAINM0; 13=GAINP0P25; 14=GAINP0P5; 15=GAINP0P75; 16=GAINP1; 17=GAINP1P25; 18=GAINP1P5; 19=GAINP1P75; 20=GAINP2; 21=GAINP2P25; 22=GAINP2P5; 23=GAINP2P75; 24=GAINP3
  [0] DIGIGAINEN — Digital Gain Enable
0x240 PRSCTRL
  [17:16] ANT1SEL, [15:14] ANT0SEL, [13:12] LOWCORRSEL, [11:10] PRESENTSEL, [9:8] SYNCSENTSEL, [7:6] WEAKSEL, [5:4] NEWWNDSEL, [3:2] ADVANCESEL, [1:0] POSTPONESEL
0x248 REALTIMCFE reset 0x1F81F4
  [31] RTCFEEN — Trecs Enable
  [30] VTAFCFRAME — Viterbi AFC FRAME Mode
  [29] SINEWEN — Enable SINE WEIGHT
  [20:18] SYNCACQWIN — SYNC Correlator Size
  [17:15] TRACKINGWIN — Correlator size for Tracking
  [14] RTSCHMODE — Real Time CFE searching mode
  [13:10] RTSCHWIN — Real time CFE searching window
  [9:0] MINCOSTTHD — Min. Cost thrshold
0x24C SEQIF
  [18] CFGANTPATTRD
  [17] ETS — Early timestamp
  [16] FRCTIMOUT — DEMOD-FRC req/ack timeout
  [15] RXTIMNF — Timing not found
  [14] RXFRAMEDETOF — Frame detection overflow
  [13] RXPRELOST — Preamble lost
  [12] RXTIMLOST — Timing lost
  [11] RXFRAMEDET1 — Frame with sync-word 1 detected
  [10] RXFRAMEDET0 — Frame with sync-word 0 detected
  [9] RXPREDET — Preamble detected
  [8] RXTIMDET — Timing detected
  [7] PHYCODEDET — CONCURRENT CODED PHY DET
  [6] PHYUNCODEDET — CONCURRENT UNCODED PHY DET
  [5] PHDSADET — PHASE DSA DETECT
  [4] LDTNOARR — No signal Detected in LDT
  [3] TXRAMPDONE — Mod ramper idle
  [2] TXPRESENT — Preamble sent
  [1] TXSYNCSENT — Sync word sent
  [0] TXFRAMESENT — Frame sent
0x250 SEQIEN
  [18] CFGANTPATTRD
  [17] ETS — Early time stamp
  [16] FRCTIMOUT — DEMOD-FRC req/ack timeout
  [15] RXTIMNF — Timing not found
  [14] RXFRAMEDETOF — Frame detection overflow
  [13] RXPRELOST — Preamble lost
  [12] RXTIMLOST — Timing lost
  [11] RXFRAMEDET1 — Frame with sync-word 1 detected
  [10] RXFRAMEDET0 — Frame with sync-word 0 detected
  [9] RXPREDET — Preamble detected
  [8] RXTIMDET — Timing detected
  [7] PHYCODEDET — CONCURRENT CODED PHY DET
  [6] PHYUNCODEDET — CONCURRENT UNCODED PHY DET
  [5] PHDSADET — PHASE DSA DETECT
  [4] LDTNOARR — No signal Detected in LDT
  [3] TXRAMPDONE — Mod ramper idle
  [2] TXPRESENT — Preamble sent
  [1] TXSYNCSENT — Sync word sent
  [0] TXFRAMESENT — Frame sent
0x254 ETSCTRL
  [29:12] CAPTRIG — Trigger to capture
  [10] CAPSIGONPRS — Capture Signal On PRS
  [9:0] ETSLOC — Early Time Stamp Location
0x258 ANTSWCTRL reset 0x3C0000
  [24:17] EXTDSTOPPULSECNT — Extend Stop Pulse Counter
  [16] ANTSWENABLE
  [15] CFGANTPATTEN — Configure Ant Pattern Enable
  [14] ANTSWRST wo — Ant SW rst pulse
  [13:12] ANTSWTYPE — Ant Switch Type
    0=US_2 (2us ant switching); 1=US_4 (4us ant switching); 2=US_6 (6us ant switching); 3=US_8 (8us ant switching)
  [11:6] ANTCOUNT — Total Ant count
  [5:0] ANTDFLTSEL — Ant Default Select
0x25C ANTSWSTART
  [17:0] ANTSWSTARTTIM — Ant switch start time
0x260 ANTSWEND
  [17:0] ANTSWENDTIM — Ant switch start time
0x264 TRECPMPATT reset 0x55555555
  [31:0] PMEXPECTPATT — Expected PM pattern
0x268 TRECPMDET reset 0x17
  [31] PREAMSCH — PM detection enable in Trecs
  [29:25] COSTHYST — PM Seaching COST HYST
  [24:23] VTPMDETSEL — Trecs PM Detection Thrshold
  [22:14] PMMINCOSTTHD — Min. Cost thrshold for Trecs PM
  [9:8] PHSCALE — PHASE Scaler
  [7:6] PMTIMEOUTSEL — PM searching timeout Threshold
  [5:3] PMCOSTVALTHD — Min COST Validation for AFC
  [2:0] PMACQUINGWIN — PM Correlator Size
0x26C CFGANTPATT
  [29:0] CFGANTPATTVAL
0x270 ETSTIM
  [17] ETSCOUNTEREN, [16:0] ETSTIMVAL
0x274 ANTSWCTRL1 reset 0x6AAAA
  [23:0] TIMEPERIOD — Time Period of xtal
0x278 COCURRMODE
  [31] CONCURRENT — CONCURRENT MODE Enable
0x27C ANTDIVCTRL
  [8] ENADPRETHRESH — Enable Preamble threshold
    0=DISABLE (Disable use of Preamble threshold after timing detection); 1=ENABLE (Enable use of Preamble threshold after timing detection)
  [7:0] ADPRETHRESH — Preamble threshold
0x280 BLEIQDSAEXT2
  [10:9] BBSSDIFFCHVAL — BBSS Diff Change Val
    {v}=GT{v} (Greater than {v}) (v=0..3)
  [8:1] BBSSDEBOUNCETIM — BBSS Debounce Time
  [0] DISMAXPEAKTRACKMODE — Disable Max Peak Track Mode
0x284 SPARE
  [7:0] SPARE
0x288 IRCALCOEFWR0
  [31] CIVWEN — CIV Coefficient Write Enable
  [30:16] CIVWD — CIV coefficient
  [15] CRVWEN — CIV Coefficient Write Enable
  [14:0] CRVWD — CRV coefficient
0x28C IRCALCOEFWR1
  fields as IRCALCOEFWR0
